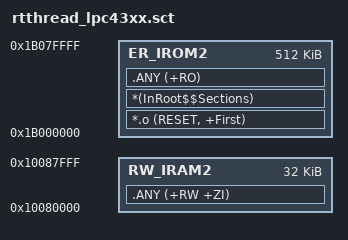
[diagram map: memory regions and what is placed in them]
; *************************************************************
; *** Scatter-Loading Description File generated by uVision ***
; *************************************************************

LR_IROM2 0x1B000000 0x00080000  {    ; load region size_region
  ER_IROM2 0x1B000000 0x00080000  {  ; load address = execution address
   *.o (RESET, +First)
   *(InRoot$$Sections)
   .ANY (+RO)
  }
  RW_IRAM2 0x10080000 0x00008000  {  ; RW data
   .ANY (+RW +ZI)
  }
}

